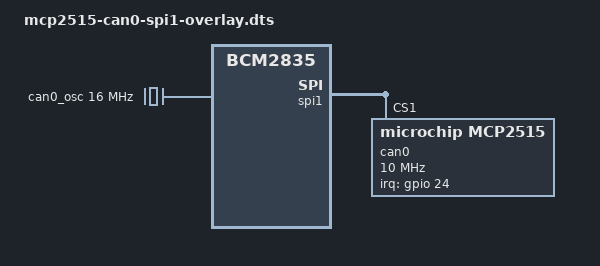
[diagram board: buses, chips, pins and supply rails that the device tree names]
/*
 * Device tree overlay for mcp251x/can0 on spi1.1
 */

/dts-v1/;
/plugin/;

/ {
    compatible = "brcm,bcm2835";
    /* disable spi-dev for spi1.1 */
    fragment@0 {
        target = <&spi1>;
        __overlay__ {
            status = "okay";
        };
    };

    fragment@1 {
	target = <&spidev1>;
	__overlay__ {
	    status = "disabled";
	};
    };

    /* the interrupt pin of the can-controller */
    fragment@2 {
        target = <&gpio>;
        __overlay__ {
            can0_pins: can0_pins {
                brcm,pins = <24>;
                brcm,function = <0>; /* input */
            };
        };
    };

    /* the clock/oscillator of the can-controller */
    fragment@3 {
        target-path = "/";
        __overlay__ {
            /* external oscillator of mcp2515 on SPI1.1 */
            can0_osc: can0_osc {
                compatible = "fixed-clock";
                #clock-cells = <0>;
                clock-frequency  = <16000000>;
            };
        };
    };

    /* the spi config of the can-controller itself binding everything together */
    fragment@4 {
        target = <&spi1>;
        __overlay__ {
            /* needed to avoid dtc warning */
            #address-cells = <1>;
            #size-cells = <0>;
            can0: mcp2515@1 {
                reg = <1>;
                compatible = "microchip,mcp2515";
                pinctrl-names = "default";
                pinctrl-0 = <&can0_pins>;
                spi-max-frequency = <10000000>;
                interrupt-parent = <&gpio>;
                interrupts = <24 8>; /* IRQ_TYPE_LEVEL_LOW */
                clocks = <&can0_osc>;
                status = "okay";
            };
        };
    };
    __overrides__ {
        oscillator = <&can0_osc>,"clock-frequency:0";
        spimaxfrequency = <&can0>,"spi-max-frequency:0";
        interrupt = <&can0_pins>,"brcm,pins:0",<&can0>,"interrupts:0";
    };
};
